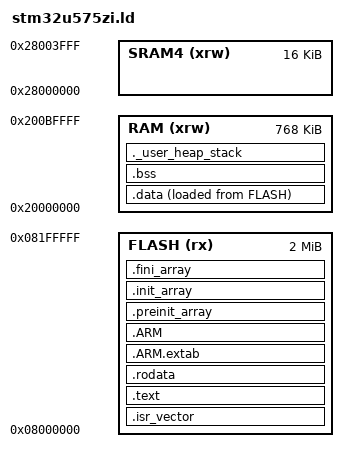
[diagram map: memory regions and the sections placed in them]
/* GNU ARM GCC linker script for the STM32U575ZIT6 "nucleo-u575" board
 * (NUCLEO-U575ZI-Q).
 *
 *   FLASH : 2048 KB @ 0x08000000
 *   RAM   :  768 KB @ 0x20000000   (SRAM1 192K + SRAM2 64K + SRAM3 512K,
 *                                   contiguous - main data + stack region)
 *   SRAM4 :   16 KB @ 0x28000000   (separate low-power domain, unused here)
 *
 * Symbols consumed by startup_stm32u575xx.s:
 *   _estack, _sidata, _sdata, _edata, _sbss, _ebss
 * Symbols consumed by syscalls.c (_sbrk): end / _end
 */

ENTRY(Reset_Handler)

MEMORY
{
  RAM   (xrw) : ORIGIN = 0x20000000, LENGTH = 768K
  SRAM4 (xrw) : ORIGIN = 0x28000000, LENGTH = 16K
  FLASH (rx)  : ORIGIN = 0x08000000, LENGTH = 2048K
}

_estack        = ORIGIN(RAM) + LENGTH(RAM);  /* top of RAM, stack grows down */
_Min_Heap_Size = 0x400;
_Min_Stack_Size = 0x1000;

SECTIONS
{
  .isr_vector :
  {
    . = ALIGN(8);
    KEEP(*(.isr_vector))
    . = ALIGN(8);
  } >FLASH

  .text :
  {
    . = ALIGN(8);
    *(.text)
    *(.text*)
    *(.glue_7)
    *(.glue_7t)
    *(.eh_frame)

    KEEP (*(.init))
    KEEP (*(.fini))

    . = ALIGN(8);
    _etext = .;
  } >FLASH

  .rodata :
  {
    . = ALIGN(8);
    *(.rodata)
    *(.rodata*)
    . = ALIGN(8);
  } >FLASH

  .ARM.extab :
  {
    *(.ARM.extab* .gnu.linkonce.armextab.*)
  } >FLASH

  .ARM :
  {
    __exidx_start = .;
    *(.ARM.exidx*)
    __exidx_end = .;
  } >FLASH

  .preinit_array :
  {
    PROVIDE_HIDDEN (__preinit_array_start = .);
    KEEP (*(.preinit_array*))
    PROVIDE_HIDDEN (__preinit_array_end = .);
  } >FLASH

  .init_array :
  {
    PROVIDE_HIDDEN (__init_array_start = .);
    KEEP (*(SORT(.init_array.*)))
    KEEP (*(.init_array*))
    PROVIDE_HIDDEN (__init_array_end = .);
  } >FLASH

  .fini_array :
  {
    PROVIDE_HIDDEN (__fini_array_start = .);
    KEEP (*(SORT(.fini_array.*)))
    KEEP (*(.fini_array*))
    PROVIDE_HIDDEN (__fini_array_end = .);
  } >FLASH

  _sidata = LOADADDR(.data);

  .data :
  {
    . = ALIGN(8);
    _sdata = .;
    __data_start__ = _sdata;
    *(.data)
    *(.data*)
    *(.RamFunc)
    *(.RamFunc*)
    . = ALIGN(8);
    _edata = .;
    __data_end__ = _edata;
  } >RAM AT> FLASH

  .bss :
  {
    . = ALIGN(8);
    _sbss = .;
    __bss_start__ = _sbss;
    *(.bss)
    *(.bss*)
    *(COMMON)
    . = ALIGN(8);
    _ebss = .;
    __bss_end__ = _ebss;
  } >RAM

  ._user_heap_stack :
  {
    . = ALIGN(8);
    PROVIDE ( end = . );
    PROVIDE ( _end = . );
    . = . + _Min_Heap_Size;
    . = . + _Min_Stack_Size;
    . = ALIGN(8);
  } >RAM

  /DISCARD/ :
  {
    libc.a ( * )
    libm.a ( * )
    libgcc.a ( * )
  }

  .ARM.attributes 0 : { *(.ARM.attributes) }
}
